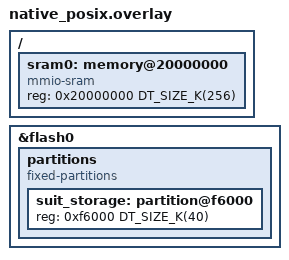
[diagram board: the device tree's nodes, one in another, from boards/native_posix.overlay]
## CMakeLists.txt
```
#
# Copyright (c) 2023 Nordic Semiconductor ASA
#
# SPDX-License-Identifier: LicenseRef-Nordic-5-Clause
#

cmake_minimum_required(VERSION 3.20.0)

find_package(Zephyr REQUIRED HINTS $ENV{ZEPHYR_BASE})

project(integration_test_suit_orchestrator)
include(../../cmake/test_template.cmake)

FILE(GLOB manifest_sources ../manifest/src/*.c)
target_sources(app PRIVATE
  ${manifest_sources}
  )

# Link with the CMake target, that includes SUIT platform internal APIs header
zephyr_library_link_libraries(suit)
zephyr_library_link_libraries(suit_orchestrator_interface)
zephyr_library_link_libraries(suit_utils)
zephyr_library_link_libraries(suit_storage_interface)
zephyr_library_link_libraries(suit_update_magic_values)
zephyr_library_link_libraries(suit_cache_interface)
zephyr_library_link_libraries(suit_execution_mode)
```

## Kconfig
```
#
# Copyright (c) 2025 Nordic Semiconductor ASA
#
# SPDX-License-Identifier: LicenseRef-Nordic-5-Clause
#

rsource "../../tests/Kconfig"

source "Kconfig.zephyr"
```

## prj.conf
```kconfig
#
# Copyright (c) 2023 Nordic Semiconductor ASA
#
# SPDX-License-Identifier: LicenseRef-Nordic-5-Clause
#

CONFIG_ZTEST=y
CONFIG_ZTEST_STACK_SIZE=4096

CONFIG_SUIT=y
CONFIG_SUIT_CRYPTO=y
CONFIG_SUIT_MCI=y
CONFIG_SUIT_MCI_IMPL_CUSTOM=y
CONFIG_PSA_WANT_ALG_ECDSA=y
CONFIG_SUIT_VALIDATOR=y
CONFIG_SUIT_VALIDATOR_IMPL_CUSTOM=y
CONFIG_SUIT_METADATA=y
CONFIG_SUIT_ORCHESTRATOR=y
CONFIG_SUIT_PROCESSOR=y
CONFIG_SUIT_PLATFORM=y
CONFIG_SUIT_LOG_LEVEL_DBG=y

CONFIG_SUIT_UTILS=y
CONFIG_SUIT_CACHE=y
# Use lower value to verify overflows
CONFIG_SUIT_CACHE_MAX_CACHES=5
CONFIG_SUIT_STORAGE=y
CONFIG_SUIT_MEMPTR_STORAGE=y
CONFIG_SUIT_EXECUTION_MODE=y

CONFIG_ZCBOR=y
CONFIG_ZCBOR_CANONICAL=y

CONFIG_FLASH=y

CONFIG_SUIT_DEVCONFIG=y
CONFIG_SUIT_PLAT_CHECK_COMPONENT_COMPATIBILITY=y
CONFIG_SUIT_PLAT_CHECK_CLASSES=y
CONFIG_SUIT_AUTHENTICATE=y

CONFIG_SUIT_DIGEST=y
CONFIG_SUIT_DIGEST_CACHE=y
CONFIG_SUIT_SINK_SELECTOR=y

CONFIG_SUIT_STREAM=y
CONFIG_SUIT_STREAM_SINK_DIGEST=y
CONFIG_SUIT_CHECK_IMAGE_MATCH=y

CONFIG_SUIT_STREAM_SINK_MEMPTR=y
CONFIG_SUIT_STREAM_SINK_FLASH=y
CONFIG_FLASH_MAP=y
CONFIG_SUIT_STREAM_SOURCE_MEMPTR=y
CONFIG_SUIT_STREAM_SOURCE_CACHE=y
```

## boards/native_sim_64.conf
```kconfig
#
# Copyright (c) 2023 Nordic Semiconductor ASA
#
# SPDX-License-Identifier: LicenseRef-Nordic-5-Clause
#

CONFIG_FLASH_SIMULATOR=y
CONFIG_FLASH_SIMULATOR_DOUBLE_WRITES=y
```

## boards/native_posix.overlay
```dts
/*
 * Copyright (c) 2023 Nordic Semiconductor ASA
 *
 * SPDX-License-Identifier: LicenseRef-Nordic-5-Clause
 */

&flash0 {
	partitions {
		compatible = "fixed-partitions";
		#address-cells = <1>;
		#size-cells = <1>;

		/* Use the last 40KB of NVM as suit storage. */
		suit_storage: partition@f6000 {
			reg = <0xf6000 DT_SIZE_K(40)>;
		};
	};
};

/ {
	sram0: memory@20000000 {
		compatible = "mmio-sram";
		reg = <0x20000000 DT_SIZE_K(256)>;
	};
};
```

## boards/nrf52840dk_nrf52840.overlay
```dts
/*
 * Copyright (c) 2023 Nordic Semiconductor ASA
 *
 * SPDX-License-Identifier: LicenseRef-Nordic-5-Clause
 */

&flash0 {
	partitions {
		compatible = "fixed-partitions";
		#address-cells = <1>;
		#size-cells = <1>;

		/* Use the last 44KB of NVM as suit storage. */
		suit_storage: partition@f5000 {
			reg = <0xf5000 DT_SIZE_K(44)>;
		};
	};
};
```

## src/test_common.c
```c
/*
 * Copyright (c) 2024 Nordic Semiconductor ASA
 *
 * SPDX-License-Identifier: LicenseRef-Nordic-5-Clause
 */

#include <zephyr/ztest.h>

#include <suit_execution_mode.h>

void check_startup_failure(void)
{
	suit_execution_mode_t mode_before = suit_execution_mode_get();
	bool has_failed = suit_execution_mode_failed();

	if (suit_execution_mode_booting()) {
		/* Update execution mode to leave transient states. */
		suit_execution_mode_startup_failed();

		/* If the device was booting - it should enter EXECUTION_MODE_FAIL_STARTUP state. */
		zassert_equal(false, suit_execution_mode_booting(),
			      "The device did not left boot mode");
		zassert_equal(false, suit_execution_mode_updating(),
			      "The device entered update mode");
		zassert_equal(true, suit_execution_mode_failed(),
			      "The device did not enter failed mode");
		zassert_equal(EXECUTION_MODE_FAIL_STARTUP, suit_execution_mode_get(),
			      "FAILED state not set after boot startup failed");
	} else if (suit_execution_mode_updating()) {
		/* Update execution mode to leave transient states. */
		suit_execution_mode_startup_failed();

		/* If the device was updating - it should enter EXECUTION_MODE_FAIL_STARTUP state.
		 */
		zassert_equal(false, suit_execution_mode_booting(), "The device entered boot mode");
		zassert_equal(false, suit_execution_mode_updating(),
			      "The device did not left update mode");
		zassert_equal(true, suit_execution_mode_failed(),
			      "The device did not enter failed mode");
		zassert_equal(EXECUTION_MODE_FAIL_STARTUP, suit_execution_mode_get(),
			      "FAILED state not set after update startup failed");
	} else {
		/* Update execution mode to leave transient states. */
		suit_execution_mode_startup_failed();

		/* If the device was in final state - it should stay in the same state state. */
		zassert_equal(false, suit_execution_mode_booting(), "The device entered boot mode");
		zassert_equal(false, suit_execution_mode_updating(),
			      "The device entered update mode");
		zassert_equal(has_failed, suit_execution_mode_failed(),
			      "The device changed failed mode");
		zassert_equal(mode_before, suit_execution_mode_get(),
			      "Unexpected execution mode change");
	}
}
```

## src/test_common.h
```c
/*
 * Copyright (c) 2024 Nordic Semiconductor ASA
 *
 * SPDX-License-Identifier: LicenseRef-Nordic-5-Clause
 */

#ifndef TEST_STARTUP_FAILURE_COMMON_H__
#define TEST_STARTUP_FAILURE_COMMON_H__

/**
 * @brief Assert that calling @ref suit_execution_mode_startup_failed in the current state
 *        is correctly handled.
 */
void check_startup_failure(void);

#endif /* TEST_STARTUP_FAILURE_COMMON_H__ */
```

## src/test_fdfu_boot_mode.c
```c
/*
 * Copyright (c) 2024 Nordic Semiconductor ASA
 *
 * SPDX-License-Identifier: LicenseRef-Nordic-5-Clause
 */

#include <zephyr/ztest.h>

#include <suit_orchestrator.h>
#include <suit_storage.h>
#include <suit_execution_mode.h>

#include <zephyr/drivers/flash.h>
#include <zephyr/storage/flash_map.h>
#include <suit_plat_mem_util.h>

#if DT_NODE_EXISTS(DT_NODELABEL(cpuapp_suit_storage))
#define SUIT_STORAGE_OFFSET FIXED_PARTITION_OFFSET(cpuapp_suit_storage)
#define SUIT_STORAGE_SIZE   FIXED_PARTITION_SIZE(cpuapp_suit_storage)
#else
#define SUIT_STORAGE_OFFSET FIXED_PARTITION_OFFSET(suit_storage)
#define SUIT_STORAGE_SIZE   FIXED_PARTITION_SIZE(suit_storage)
#endif
#define SUIT_STORAGE_ADDRESS suit_plat_mem_nvm_ptr_get(SUIT_STORAGE_OFFSET)
#define ZEPHYR_FLASH_EB_SIZE DT_PROP(DT_CHOSEN(zephyr_flash), erase_block_size)

/* RFC4122 uuid5(nordic_vid, 'test_sample_recovery')
 */
static const suit_manifest_class_id_t recovery_class_id = {{0x74, 0xa0, 0xc6, 0xe7, 0xa9, 0x2a,
							    0x56, 0x00, 0x9c, 0x5d, 0x30, 0xee,
							    0x87, 0x8b, 0x06, 0xba}};

/* Empty recovery envelope with invoke sequence */
extern const uint8_t manifest_recovery_no_validate_buf[];
extern const size_t manifest_recovery_no_validate_len;

/* Empty recovery envelope with invoke and failig validate sequences */
extern const uint8_t manifest_recovery_validate_fail_buf[];
extern const size_t manifest_recovery_validate_fail_len;

/* Empty recovery envelope with validate, invoke and failing load sequences */
extern const uint8_t manifest_recovery_validate_load_fail_buf[];
extern const size_t manifest_recovery_validate_load_fail_len;

/* Empty recovery envelope with validate and load sequences */
extern const uint8_t manifest_recovery_validate_load_no_invoke_buf[];
extern const size_t manifest_recovery_validate_load_no_invoke_len;

/* Empty recovery envelope with validate, load and failing invoke sequences */
extern const uint8_t manifest_recovery_validate_load_invoke_fail_buf[];
extern const size_t manifest_recovery_validate_load_invoke_fail_len;

/* Empty recovery envelope with validate, load and invoke sequences */
extern const uint8_t manifest_recovery_validate_load_invoke_buf[];
extern const size_t manifest_recovery_validate_load_invoke_len;

/* Valid recovery envelope */
extern uint8_t manifest_valid_recovery_buf[];
extern size_t manifest_valid_recovery_len;

/* Originally valid recovery envelope with manipulated single byte */
extern const uint8_t manifest_manipulated_recovery_buf[];
extern const size_t manifest_manipulated_recovery_len;

/* Random bytes, attached to the envelopes as FW. */
extern const uint8_t sample_fw_buf[];
extern const size_t sample_fw_len;
extern const uintptr_t sample_recovery_fw_address;

static void *setup_install_recovery_fw(void)
{
	int err = 0;
	uint8_t *sample_recovery_fw_ptr = suit_plat_mem_ptr_get(sample_recovery_fw_address);
	uintptr_t sample_recovery_fw_offset = suit_plat_mem_nvm_offset_get(sample_recovery_fw_ptr);

	/* Clear the whole application area */
	const struct device *fdev = SUIT_PLAT_INTERNAL_NVM_DEV;

	zassert_not_null(fdev, "Unable to find a driver to erase storage area");

	if (sample_fw_len > ZEPHYR_FLASH_EB_SIZE) {
		err = flash_erase(fdev, sample_recovery_fw_offset, sample_fw_len);
	} else {
		err = flash_erase(fdev, sample_recovery_fw_offset, ZEPHYR_FLASH_EB_SIZE);
	}
	zassert_equal(0, err, "Unable to erase test FW area before test execution");

	err = flash_write(fdev, sample_recovery_fw_offset, sample_fw_buf, sample_fw_len);
	zassert_equal(0, err, "Unable to write test FW area before test execution");

	return NULL;
}

static void setup_erased_flash(void)
{
	/* Execute SUIT storage init, so the MPI area is copied into a backup region. */
	int err = suit_storage_init();

	zassert_equal(SUIT_PLAT_SUCCESS, err, "Failed to init and backup suit storage (%d)", err);

	/* Clear the whole application area */
	const struct device *fdev = SUIT_PLAT_INTERNAL_NVM_DEV;

	zassert_not_null(fdev, "Unable to find a driver to erase storage area");

	err = flash_erase(fdev, SUIT_STORAGE_OFFSET, SUIT_STORAGE_SIZE);
	zassert_equal(0, err, "Unable to erase storage before test execution");

	suit_plat_err_t ret = suit_storage_flags_clear(SUIT_FLAG_RECOVERY);

	zassert_equal(SUIT_PLAT_SUCCESS, ret,
		      "Unable to clear recovery flag before test execution");

	ret = suit_storage_flags_clear(SUIT_FLAG_FOREGROUND_DFU);
	zassert_equal(SUIT_PLAT_SUCCESS, ret,
		      "Unable to clear foreground DFU flag before test execution");

	/* Recover MPI area from the backup region. */
	err = suit_storage_init();
	zassert_equal(SUIT_PLAT_SUCCESS, err, "Failed to recover MPI area from backup (%d)", err);
}

static void setup_install_envelope(const suit_manifest_class_id_t *class_id, const uint8_t *buf,
				   size_t len)
{
	suit_plat_err_t err = suit_storage_install_envelope(class_id, (uint8_t *)buf, len);

	zassert_equal(SUIT_PLAT_SUCCESS, err,
		      "Unable to install envelope before test execution (0x%x, %d)", buf, len);
}

static void setup_fdfu_flag(void)
{
	zassert_equal(SUIT_PLAT_SUCCESS, suit_storage_flags_set(SUIT_FLAG_FOREGROUND_DFU),
		      "Unable to set foreground DFU flag before test execution");
}

ZTEST_SUITE(orchestrator_fdfu_boot_tests, NULL, setup_install_recovery_fw, NULL, NULL, NULL);

ZTEST(orchestrator_fdfu_boot_tests, test_fdfu_no_recovery_envelope)
{
	/* GIVEN empty flash (suit storage is erased)... */
	setup_erased_flash();
	/* ... and update candidate flag is not set... */
	/* ... and foreground DFU flag is set */
	setup_fdfu_flag();
	/* ... and orchestrator is initialized... */
	zassert_equal(0, suit_orchestrator_init(),
		      "Orchestrator not initialized before test execution");
	/* ... and the execution mode is set to foreground DFU boot */
	zassert_equal(EXECUTION_MODE_INVOKE_FOREGROUND_DFU, suit_execution_mode_get(),
		      "Unexpected execution mode before test execution");

	/* WHEN orchestrator is executed */
	int err = suit_orchestrator_entry();

	/* THEN orchestrator fails (hard)... */
	zassert_equal(-ENOENT, err, "Orchestrator did not fail");
	/* ... and the foreground DFU flag is set... */
	zassert_equal(SUIT_PLAT_ERR_NOT_FOUND, suit_storage_flags_check(SUIT_FLAG_RECOVERY),
		      "Recovery flag set");
	zassert_equal(SUIT_PLAT_SUCCESS, suit_storage_flags_check(SUIT_FLAG_FOREGROUND_DFU),
		      "Foreground DFU flag not set");
	/* ... and the execution mode is set to the FAIL INVOKE FDFU */
	zassert_equal(EXECUTION_MODE_FAIL_INVOKE_FOREGROUND_DFU, suit_execution_mode_get(),
		      "Execution mode not changed to the FAIL INVOKE FDFU");
	/* ... and execution mode indicates a failed state */
	zassert_equal(true, suit_execution_mode_failed(), "The device does not enter failed mode");
	/* ... and execution mode does not indicate boot mode */
	zassert_equal(false, suit_execution_mode_booting(), "The device did not left boot mode");
	/* ... and execution mode does not indicate update mode */
	zassert_equal(false, suit_execution_mode_updating(), "The device entered update mode");
}

ZTEST(orchestrator_fdfu_boot_tests, test_fdfu_invalid_recovery_envelope)
{
	/* GIVEN empty flash (suit storage is erased)... */
	setup_erased_flash();
	/* ... and recovery envelope is installed... */
	setup_install_envelope(&recovery_class_id, manifest_manipulated_recovery_buf,
			       manifest_manipulated_recovery_len);
	/* ... and update candidate flag is not set... */
	/* ... and foreground DFU flag is set */
	setup_fdfu_flag();
	/* ... and orchestrator is initialized... */
	zassert_equal(0, suit_orchestrator_init(),
		      "Orchestrator not initialized before test execution");
	/* ... and the execution mode is set to foreground DFU boot */
	zassert_equal(EXECUTION_MODE_INVOKE_FOREGROUND_DFU, suit_execution_mode_get(),
		      "Unexpected execution mode before test execution");

	/* WHEN orchestrator is executed */
	int err = suit_orchestrator_entry();

	/* THEN orchestrator fails (hard)... */
	zassert_equal(-ENOEXEC, err, "Orchestrator did not fail");
	/* ... and the foreground DFU flag is set... */
	zassert_equal(SUIT_PLAT_ERR_NOT_FOUND, suit_storage_flags_check(SUIT_FLAG_RECOVERY),
		      "Recovery flag set");
	zassert_equal(SUIT_PLAT_SUCCESS, suit_storage_flags_check(SUIT_FLAG_FOREGROUND_DFU),
		      "Foreground DFU flag not set");
	/* ... and the execution mode is set to the FAIL INVOKE FDFU */
	zassert_equal(EXECUTION_MODE_FAIL_INVOKE_FOREGROUND_DFU, suit_execution_mode_get(),
		      "Execution mode not changed to the FAIL INVOKE FDFU");
}

ZTEST(orchestrator_fdfu_boot_tests, test_fdfu_valid_recovery_envelope)
{
	/* GIVEN empty flash (suit storage is erased)... */
	setup_erased_flash();
	/* ... and recovery envelope is installed... */
	setup_install_envelope(&recovery_class_id, manifest_valid_recovery_buf,
			       manifest_valid_recovery_len);
	/* ... and update candidate flag is not set... */
	/* ... and foreground DFU flag is set */
	setup_fdfu_flag();
	/* ... and orchestrator is initialized... */
	zassert_equal(0, suit_orchestrator_init(),
		      "Orchestrator not initialized before test execution");
	/* ... and the execution mode is set to foreground DFU boot */
	zassert_equal(EXECUTION_MODE_INVOKE_FOREGROUND_DFU, suit_execution_mode_get(),
		      "Unexpected execution mode before test execution");

	/* WHEN orchestrator is executed */
	int err = suit_orchestrator_entry();

	/* THEN orchestrator succeeds... */
	zassert_equal(0, err, "Orchestrator not initialized");
	/* ... and the foreground DFU flag is set... */
	zassert_equal(SUIT_PLAT_ERR_NOT_FOUND, suit_storage_flags_check(SUIT_FLAG_RECOVERY),
		      "Recovery flag set");
	zassert_equal(SUIT_PLAT_SUCCESS, suit_storage_flags_check(SUIT_FLAG_FOREGROUND_DFU),
		      "Foreground DFU flag not set");
	/* ... and the execution mode is set to the POST INVOKE FDFU */
	zassert_equal(EXECUTION_MODE_POST_INVOKE_FOREGROUND_DFU, suit_execution_mode_get(),
		      "Execution mode not changed to the POST INVOKE FDFU");
	/* ... and execution mode does not indicate a failed state */
	zassert_equal(false, suit_execution_mode_failed(), "The device entered failed mode");
	/* ... and execution mode does not indicate boot mode */
	zassert_equal(false, suit_execution_mode_booting(), "The device did not left boot mode");
	/* ... and execution mode does not indicate update mode */
	zassert_equal(false, suit_execution_mode_updating(), "The device entered update mode");
}

ZTEST(orchestrator_fdfu_boot_tests, test_fdfu_seq_no_validate)
{
	/* GIVEN empty flash (suit storage is erased)... */
	setup_erased_flash();
	/* ... and recovery envelope is installed... */
	setup_install_envelope(&recovery_class_id, manifest_recovery_no_validate_buf,
			       manifest_recovery_no_validate_len);
	/* ... and update candidate flag is not set... */
	/* ... and foreground DFU flag is set */
	setup_fdfu_flag();
	/* ... and orchestrator is initialized... */
	zassert_equal(0, suit_orchestrator_init(),
		      "Orchestrator not initialized before test execution");
	/* ... and the execution mode is set to foreground DFU boot */
	zassert_equal(EXECUTION_MODE_INVOKE_FOREGROUND_DFU, suit_execution_mode_get(),
		      "Unexpected execution mode before test execution");

	/* WHEN orchestrator is executed */
	int err = suit_orchestrator_entry();

	/* THEN orchestrator succeeds... */
	zassert_equal(0, err, "Envelope without validate sequence not accepted (err: %d)", err);
	/* ... and the foreground DFU flag is set... */
	zassert_equal(SUIT_PLAT_ERR_NOT_FOUND, suit_storage_flags_check(SUIT_FLAG_RECOVERY),
		      "Recovery flag set");
	zassert_equal(SUIT_PLAT_SUCCESS, suit_storage_flags_check(SUIT_FLAG_FOREGROUND_DFU),
		      "Foreground DFU flag not set");
	/* ... and the execution mode is set to the POST INVOKE RECOVERY */
	zassert_equal(EXECUTION_MODE_POST_INVOKE_FOREGROUND_DFU, suit_execution_mode_get(),
		      "Execution mode not changed to the POST INVOKE FDFU");
}

ZTEST(orchestrator_fdfu_boot_tests, test_fdfu_seq_validate_fail)
{
	/* GIVEN empty flash (suit storage is erased)... */
	setup_erased_flash();
	/* ... and recovery envelope with failing suit-validate sequence is installed... */
	setup_install_envelope(&recovery_class_id, manifest_recovery_validate_fail_buf,
			       manifest_recovery_validate_fail_len);
	/* ... and update candidate flag is not set... */
	/* ... and foreground DFU flag is set */
	setup_fdfu_flag();
	/* ... and orchestrator is initialized... */
	zassert_equal(0, suit_orchestrator_init(),
		      "Orchestrator not initialized before test execution");
	/* ... and the execution mode is set to foreground DFU boot */
	zassert_equal(EXECUTION_MODE_INVOKE_FOREGROUND_DFU, suit_execution_mode_get(),
		      "Unexpected execution mode before test execution");

	/* WHEN orchestrator is executed */
	int err = suit_orchestrator_entry();

	/* THEN orchestrator fails (hard)... */
	zassert_equal(-EILSEQ, err, "Orchestrator did not fail");
	/* ... and the foreground DFU flag is set... */
	zassert_equal(SUIT_PLAT_ERR_NOT_FOUND, suit_storage_flags_check(SUIT_FLAG_RECOVERY),
		      "Recovery flag set");
	zassert_equal(SUIT_PLAT_SUCCESS, suit_storage_flags_check(SUIT_FLAG_FOREGROUND_DFU),
		      "Foreground DFU flag not set");
	/* ... and the execution mode is set to the FAIL INVOKE FDFU */
	zassert_equal(EXECUTION_MODE_FAIL_INVOKE_FOREGROUND_DFU, suit_execution_mode_get(),
		      "Execution mode not changed to the FAIL INVOKE FDFU");
}

ZTEST(orchestrator_fdfu_boot_tests, test_fdfu_seq_validate_load_fail)
{
	/* GIVEN empty flash (suit storage is erased)... */
	setup_erased_flash();
	/* ... and recovery envelope with failing suit-load sequence is installed... */
	setup_install_envelope(&recovery_class_id, manifest_recovery_validate_load_fail_buf,
			       manifest_recovery_validate_load_fail_len);
	/* ... and update candidate flag is not set... */
	/* ... and foreground DFU flag is set */
	setup_fdfu_flag();
	/* ... and orchestrator is initialized... */
	zassert_equal(0, suit_orchestrator_init(),
		      "Orchestrator not initialized before test execution");
	/* ... and the execution mode is set to foreground DFU boot */
	zassert_equal(EXECUTION_MODE_INVOKE_FOREGROUND_DFU, suit_execution_mode_get(),
		      "Unexpected execution mode before test execution");

	/* WHEN orchestrator is executed */
	int err = suit_orchestrator_entry();

	/* THEN orchestrator fails (hard)... */
	zassert_equal(-EILSEQ, err, "Orchestrator did not fail");
	/* ... and the foreground DFU flag is set... */
	zassert_equal(SUIT_PLAT_ERR_NOT_FOUND, suit_storage_flags_check(SUIT_FLAG_RECOVERY),
		      "Recovery flag set");
	zassert_equal(SUIT_PLAT_SUCCESS, suit_storage_flags_check(SUIT_FLAG_FOREGROUND_DFU),
		      "Foreground DFU flag not set");
	/* ... and the execution mode is set to the FAIL INVOKE FDFU */
	zassert_equal(EXECUTION_MODE_FAIL_INVOKE_FOREGROUND_DFU, suit_execution_mode_get(),
		      "Execution mode not changed to the FAIL INVOKE FDFU");
}

ZTEST(orchestrator_fdfu_boot_tests, test_fdfu_seq_validate_load_no_invoke)
{
	/* GIVEN empty flash (suit storage is erased)... */
	setup_erased_flash();
	/* ... and recovery envelope without suit-invoke sequence is installed... */
	setup_install_envelope(&recovery_class_id, manifest_recovery_validate_load_no_invoke_buf,
			       manifest_recovery_validate_load_no_invoke_len);
	/* ... and update candidate flag is not set... */
	/* ... and foreground DFU flag is set */
	setup_fdfu_flag();
	/* ... and orchestrator is initialized... */
	zassert_equal(0, suit_orchestrator_init(),
		      "Orchestrator not initialized before test execution");
	/* ... and the execution mode is set to foreground DFU boot */
	zassert_equal(EXECUTION_MODE_INVOKE_FOREGROUND_DFU, suit_execution_mode_get(),
		      "Unexpected execution mode before test execution");

	/* WHEN orchestrator is executed */
	int err = suit_orchestrator_entry();

	/* THEN orchestrator fails (hard)... */
	zassert_equal(-EILSEQ, err, "Orchestrator did not fail");
	/* ... and the foreground DFU flag is set... */
	zassert_equal(SUIT_PLAT_ERR_NOT_FOUND, suit_storage_flags_check(SUIT_FLAG_RECOVERY),
		      "Recovery flag set");
	zassert_equal(SUIT_PLAT_SUCCESS, suit_storage_flags_check(SUIT_FLAG_FOREGROUND_DFU),
		      "Foreground DFU flag not set");
	/* ... and the execution mode is set to the FAIL INVOKE FDFU */
	zassert_equal(EXECUTION_MODE_FAIL_INVOKE_FOREGROUND_DFU, suit_execution_mode_get(),
		      "Execution mode not changed to the FAIL INVOKE FDFU");
}

ZTEST(orchestrator_fdfu_boot_tests, test_fdfu_seq_validate_load_invoke_fail)
{
	/* GIVEN empty flash (suit storage is erased)... */
	setup_erased_flash();
	/* ... and recovery envelope with failing suit-invoke sequence is installed... */
	setup_install_envelope(&recovery_class_id, manifest_recovery_validate_load_invoke_fail_buf,
			       manifest_recovery_validate_load_invoke_fail_len);
	/* ... and update candidate flag is not set... */
	/* ... and foreground DFU flag is set */
	setup_fdfu_flag();
	/* ... and orchestrator is initialized... */
	zassert_equal(0, suit_orchestrator_init(),
		      "Orchestrator not initialized before test execution");
	/* ... and the execution mode is set to foreground DFU boot */
	zassert_equal(EXECUTION_MODE_INVOKE_FOREGROUND_DFU, suit_execution_mode_get(),
		      "Unexpected execution mode before test execution");

	/* WHEN orchestrator is executed */
	int err = suit_orchestrator_entry();

	/* THEN orchestrator fails (hard)... */
	zassert_equal(-EILSEQ, err, "Orchestrator did not fail");
	/* ... and the foreground DFU flag is set... */
	zassert_equal(SUIT_PLAT_ERR_NOT_FOUND, suit_storage_flags_check(SUIT_FLAG_RECOVERY),
		      "Recovery flag set");
	zassert_equal(SUIT_PLAT_SUCCESS, suit_storage_flags_check(SUIT_FLAG_FOREGROUND_DFU),
		      "Foreground DFU flag not set");
	/* ... and the execution mode is set to the FAIL INVOKE FDFU */
	zassert_equal(EXECUTION_MODE_FAIL_INVOKE_FOREGROUND_DFU, suit_execution_mode_get(),
		      "Execution mode not changed to the FAIL INVOKE FDFU");
}

ZTEST(orchestrator_fdfu_boot_tests, test_fdfu_seq_validate_load_invoke)
{
	/* GIVEN empty flash (suit storage is erased)... */
	setup_erased_flash();
	/* ... and recovery envelope without dependencies is installed... */
	setup_install_envelope(&recovery_class_id, manifest_recovery_validate_load_invoke_buf,
			       manifest_recovery_validate_load_invoke_len);
	/* ... and update candidate flag is not set... */
	/* ... and foreground DFU flag is set */
	setup_fdfu_flag();
	/* ... and orchestrator is initialized... */
	zassert_equal(0, suit_orchestrator_init(),
		      "Orchestrator not initialized before test execution");
	/* ... and the execution mode is set to foreground DFU boot */
	zassert_equal(EXECUTION_MODE_INVOKE_FOREGROUND_DFU, suit_execution_mode_get(),
		      "Unexpected execution mode before test execution");

	/* WHEN orchestrator is executed */
	int err = suit_orchestrator_entry();

	/* THEN orchestrator fails succeeds... */
	zassert_equal(0, err, "Orchestrator not initialized");
	/* ... and the foreground DFU flag is set... */
	zassert_equal(SUIT_PLAT_ERR_NOT_FOUND, suit_storage_flags_check(SUIT_FLAG_RECOVERY),
		      "Recovery flag set");
	zassert_equal(SUIT_PLAT_SUCCESS, suit_storage_flags_check(SUIT_FLAG_FOREGROUND_DFU),
		      "Foreground DFU flag not set");
	/* ... and the execution mode is set to the POST INVOKE FDFU */
	zassert_equal(EXECUTION_MODE_POST_INVOKE_FOREGROUND_DFU, suit_execution_mode_get(),
		      "Execution mode not changed to the POST INVOKE FDFU");
}
```

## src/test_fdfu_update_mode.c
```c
/*
 * Copyright (c) 2024 Nordic Semiconductor ASA
 *
 * SPDX-License-Identifier: LicenseRef-Nordic-5-Clause
 */

#include <zephyr/ztest.h>

#include <suit_orchestrator.h>
#include <suit_storage.h>
#include <suit_execution_mode.h>
#include <suit_dfu_cache.h>

#include <zephyr/drivers/flash.h>
#include <zephyr/storage/flash_map.h>
#include <suit_plat_mem_util.h>

#if DT_NODE_EXISTS(DT_NODELABEL(cpuapp_suit_storage))
#define SUIT_STORAGE_OFFSET FIXED_PARTITION_OFFSET(cpuapp_suit_storage)
#define SUIT_STORAGE_SIZE   FIXED_PARTITION_SIZE(cpuapp_suit_storage)
#else
#define SUIT_STORAGE_OFFSET FIXED_PARTITION_OFFSET(suit_storage)
#define SUIT_STORAGE_SIZE   FIXED_PARTITION_SIZE(suit_storage)
#endif

/* RFC4122 uuid5(nordic_vid, 'test_sample_app') */
static const suit_manifest_class_id_t supported_class_id = {{0x5b, 0x46, 0x9f, 0xd1, 0x90, 0xee,
							     0x53, 0x9c, 0xa3, 0x18, 0x68, 0x1b,
							     0x03, 0x69, 0x5e, 0x36}};

/* RFC4122 uuid5(nordic_vid, 'test_sample_root') */
static const suit_manifest_class_id_t root_class_id = {{0x97, 0x05, 0x48, 0x23, 0x4c, 0x3d, 0x59,
							0xa1, 0x89, 0x86, 0xa5, 0x46, 0x60, 0xa1,
							0x4b, 0x0a}};

/* Valid root envelope */
extern uint8_t manifest_valid_buf[];
extern size_t manifest_valid_len;

/* Valid recovery envelope */
extern uint8_t manifest_valid_recovery_buf[];
extern size_t manifest_valid_recovery_len;

static void setup_erased_flash(void)
{
	/* Clear the whole application area */
	const struct device *fdev = SUIT_PLAT_INTERNAL_NVM_DEV;

	zassert_not_null(fdev, "Unable to find a driver to erase storage area");

	int err = flash_erase(fdev, SUIT_STORAGE_OFFSET, SUIT_STORAGE_SIZE);

	zassert_equal(0, err, "Unable to erase storage before test execution");

	suit_plat_err_t ret = suit_storage_flags_clear(SUIT_FLAG_RECOVERY);

	zassert_equal(SUIT_PLAT_SUCCESS, ret,
		      "Unable to clear recovery flag before test execution");

	ret = suit_storage_flags_clear(SUIT_FLAG_FOREGROUND_DFU);
	zassert_equal(SUIT_PLAT_SUCCESS, ret,
		      "Unable to clear foreground DFU flag before test execution");

	/* Recover MPI area from the backup region. */
	err = suit_storage_init();
	zassert_equal(SUIT_PLAT_SUCCESS, err, "Failed to recover MPI area from backup (%d)", err);
}

static void setup_update_candidate(const uint8_t *buf, size_t len)
{
	zassert_not_null(buf, "NULL buf");

	suit_plat_mreg_t update_candidate[1] = {{
		.mem = buf,
		.size = len,
	}};

	int err = suit_storage_update_cand_set(update_candidate, ARRAY_SIZE(update_candidate));

	zassert_equal(SUIT_PLAT_SUCCESS, err,
		      "Unable to set update candidate before test execution (0x%x, %d)", buf, len);
}

static void assert_post_fdfu_install_state(void)
{
	const suit_plat_mreg_t *regions = NULL;
	size_t len = 0;

	/* Each install attempt must at the end: */
	/* - clear the candidate availability flag */
	suit_plat_err_t ret = suit_storage_update_cand_get(&regions, &len);

	zassert_equal(SUIT_PLAT_ERR_NOT_FOUND, ret, "Update candidate presence not cleared");
	/* - clear the foreground DFU flag */
	zassert_equal(SUIT_PLAT_ERR_NOT_FOUND, suit_storage_flags_check(SUIT_FLAG_FOREGROUND_DFU),
		      "Foreground DFU flag not cleared");
	/* - do not modify the execution mode */
	zassert_equal(EXECUTION_MODE_INSTALL_FOREGROUND_DFU, suit_execution_mode_get(),
		      "Execution mode modified");
}

static void assert_post_fdfu_install_failed_state(void)
{
	const suit_plat_mreg_t *regions = NULL;
	size_t len = 0;

	/* Each install attempt must at the end: */
	/* - clear the candidate availability flag */
	suit_plat_err_t ret = suit_storage_update_cand_get(&regions, &len);

	zassert_equal(SUIT_PLAT_ERR_NOT_FOUND, ret, "Update candidate presence not cleared");
	/* - do not modify the foreground DFU flag */
	zassert_equal(SUIT_PLAT_ERR_NOT_FOUND, suit_storage_flags_check(SUIT_FLAG_RECOVERY),
		      "Recovery flag changed");
	zassert_equal(SUIT_PLAT_SUCCESS, suit_storage_flags_check(SUIT_FLAG_FOREGROUND_DFU),
		      "Foreground DFU flag changed");
	/* - do not modify the execution mode */
	zassert_equal(EXECUTION_MODE_INSTALL_FOREGROUND_DFU, suit_execution_mode_get(),
		      "Execution mode modified");
}

static void orchestrator_tests_cleanup(void *fixture)
{
	(void)fixture;
	suit_dfu_cache_deinitialize();
}

static void enter_fdfu_mode(void *fixture)
{
	int err = suit_storage_init();

	zassert_equal(SUIT_PLAT_SUCCESS, err, "Failed to init and backup suit storage (%d)", err);

	setup_erased_flash();

	zassert_equal(SUIT_PLAT_SUCCESS, suit_storage_flags_set(SUIT_FLAG_FOREGROUND_DFU),
		      "Unable to set foreground DFU flag before test execution");
}

ZTEST_SUITE(orchestrator_fdfu_update_tests, NULL, NULL, enter_fdfu_mode,
	    orchestrator_tests_cleanup, NULL);

ZTEST(orchestrator_fdfu_update_tests, test_fdfu_successful_update)
{
	const uint8_t *addr;
	size_t size;

	/* GIVEN valid update candidate in suit storage... */
	setup_update_candidate(manifest_valid_buf, manifest_valid_len);
	/* ... and suit orchestrator is initialized... */
	zassert_equal(0, suit_orchestrator_init(), "Orchestrator not initialized");
	/* ... and the execution mode is set to install foreground DFU mode */
	zassert_equal(EXECUTION_MODE_INSTALL_FOREGROUND_DFU, suit_execution_mode_get(),
		      "Unexpected execution mode before test execution");

	/* WHEN orchestrator is launched */
	int err = suit_orchestrator_entry();

	/* THEN installation is performed successfully... */
	/* ... and orchestrator exits without an error... */
	zassert_equal(0, err, "Unexpected error code");
	/* ... and the application envelope get installed... */
	err = suit_storage_installed_envelope_get(&supported_class_id, &addr, &size);
	zassert_equal(SUIT_PLAT_SUCCESS, err,
		      "The application envelope was not installed after successful update");
	/* ... and the root envelope get installed... */
	err = suit_storage_installed_envelope_get(&root_class_id, &addr, &size);
	zassert_equal(SUIT_PLAT_SUCCESS, err,
		      "The root envelope was not installed after successful update");
	/* ... and the candidate availability flag is cleared */
	assert_post_fdfu_install_state();
}

ZTEST(orchestrator_fdfu_update_tests, test_fdfu_successful_update_and_boot)
{
	const uint8_t *addr_boot;
	size_t size_boot;
	const uint8_t *addr_update;
	size_t size_update;

	/* GIVEN valid update candidate in suit storage... */
	setup_update_candidate(manifest_valid_buf, manifest_valid_len);
	/* ... and suit orchestrator is initialized... */
	zassert_equal(0, suit_orchestrator_init(), "Orchestrator not initialized first time");
	/* ... and the execution mode is set to install foreground DFU mode */
	zassert_equal(EXECUTION_MODE_INSTALL_FOREGROUND_DFU, suit_execution_mode_get(),
		      "Unexpected execution mode before test execution");
	/* ... and orchestrator is launched first time to perform successful update... */
	zassert_equal(0, suit_orchestrator_entry(), "Unsuccessful first orchestrator launch");
	/* ... and the root envelope is installed... */
	int err = suit_storage_installed_envelope_get(&root_class_id, &addr_boot, &size_boot);

	zassert_equal(SUIT_PLAT_SUCCESS, err,
		      "The root envelope was not installed after successful update");
	/* ... and the application envelope is installed... */
	err = suit_storage_installed_envelope_get(&supported_class_id, &addr_boot, &size_boot);
	zassert_equal(SUIT_PLAT_SUCCESS, err,
		      "The application envelope was not installed after successful update");
	/* ... and the candidate availability flag is cleared */
	assert_post_fdfu_install_state();

	/* WHEN orchestrator is initialized again (reboot simulation)... */
	zassert_equal(0, suit_orchestrator_init(), "Orchestrator not initialized second time");
	/* ... and the execution mode is set to invoke mode */
	zassert_equal(EXECUTION_MODE_INVOKE, suit_execution_mode_get(),
		      "Unexpected execution mode before test execution");
	/* ... and orchestrator is launched again */
	err = suit_orchestrator_entry();

	/* THEN installed SW is invoked successfully (orchestrator returns no error)... */
	zassert_equal(0, err, "Unexpected error code");
	/* ... and the root envelope remains installed... */
	err = suit_storage_installed_envelope_get(&root_class_id, &addr_update, &size_update);
	zassert_equal(SUIT_PLAT_SUCCESS, err,
		      "The root envelope was not installed after successful update");
	/* ... and the envelope remains installed... */
	err = suit_storage_installed_envelope_get(&supported_class_id, &addr_update, &size_update);
	zassert_equal(SUIT_PLAT_SUCCESS, err,
		      "The application envelope was not installed after successful update");
	/* .. and the same index in SUIT storage is used... */
	zassert_equal(addr_boot, addr_update,
		      "The envelope was not installed in the same SUIT storage slot");
	/* ... and the execution mode is set to post invoke mode */
	zassert_equal(EXECUTION_MODE_POST_INVOKE, suit_execution_mode_get(),
		      "Unexpected execution mode after test execution");
}

ZTEST(orchestrator_fdfu_update_tests, test_fdfu_invalid_exec_mode)
{
	/* GIVEN suit storage does not indicate presence of update candidate... */
	setup_erased_flash();
	/* ... and orchestrator is initialized... */
	zassert_equal(0, suit_orchestrator_init(), "Orchestrator not initialized");
	/* ... and the execution mode is forced to foreground DFU install mode */
	zassert_equal(SUIT_PLAT_SUCCESS,
		      suit_execution_mode_set(EXECUTION_MODE_INSTALL_FOREGROUND_DFU),
		      "Unable to override execution mode before test execution");

	/* WHEN orchestrator is launched */
	int err = suit_orchestrator_entry();

	/* THEN orchestrator returns error code... */
	zassert_equal(-EMSGSIZE, err, "Unexpected error code");
	/* ... and the candidate availability flag remains cleared */
	assert_post_fdfu_install_state();
}

ZTEST(orchestrator_fdfu_update_tests, test_fdfu_independent_updates_denied)
{
	/* GIVEN suit storage contains recovery FW update... */
	setup_update_candidate(manifest_valid_recovery_buf, manifest_valid_recovery_len);

	/* ... and orchestrator is initialized... */
	zassert_equal(0, suit_orchestrator_init(), "Orchestrator not initialized");
	/* ... and the execution mode is set to install foreground DFU mode */
	zassert_equal(EXECUTION_MODE_INSTALL_FOREGROUND_DFU, suit_execution_mode_get(),
		      "Unexpected execution mode before test execution");

	/* WHEN orchestrator is launched */
	int err = suit_orchestrator_entry();

	/* THEN orchestrator returns error code... */
	zassert_equal(-EACCES, err, "Unexpected error code");
	/* ... and the candidate availability flag is cleared */
	assert_post_fdfu_install_failed_state();
}
```

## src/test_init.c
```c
/*
 * Copyright (c) 2024 Nordic Semiconductor ASA
 *
 * SPDX-License-Identifier: LicenseRef-Nordic-5-Clause
 */

#include <zephyr/ztest.h>

#include <suit_orchestrator.h>
#include <suit_storage.h>
#include <suit_execution_mode.h>

#include <zephyr/drivers/flash.h>
#include <zephyr/storage/flash_map.h>
#include <suit_plat_mem_util.h>
#include "test_common.h"

#if DT_NODE_EXISTS(DT_NODELABEL(cpuapp_suit_storage))
#define SUIT_STORAGE_OFFSET FIXED_PARTITION_OFFSET(cpuapp_suit_storage)
#define SUIT_STORAGE_SIZE   FIXED_PARTITION_SIZE(cpuapp_suit_storage)
#else
#define SUIT_STORAGE_OFFSET FIXED_PARTITION_OFFSET(suit_storage)
#define SUIT_STORAGE_SIZE   FIXED_PARTITION_SIZE(suit_storage)
#endif
#define SUIT_STORAGE_ADDRESS suit_plat_mem_nvm_ptr_get(SUIT_STORAGE_OFFSET)

/* Valid envelope */
extern uint8_t manifest_valid_buf[];
extern size_t manifest_valid_len;

static void setup_erased_flash(void)
{
	/* Execute SUIT storage init, so the MPI area is copied into a backup region. */
	int err = suit_storage_init();

	zassert_equal(SUIT_PLAT_SUCCESS, err, "Failed to init and backup suit storage (%d)", err);

	/* Clear the whole application area */
	const struct device *fdev = SUIT_PLAT_INTERNAL_NVM_DEV;

	zassert_not_null(fdev, "Unable to find a driver to erase storage area");

	err = flash_erase(fdev, SUIT_STORAGE_OFFSET, SUIT_STORAGE_SIZE);
	zassert_equal(0, err, "Unable to erase storage before test execution");

	suit_plat_err_t ret = suit_storage_flags_clear(SUIT_FLAG_RECOVERY);

	zassert_equal(SUIT_PLAT_SUCCESS, ret,
		      "Unable to clear recovery flag before test execution");

	ret = suit_storage_flags_clear(SUIT_FLAG_FOREGROUND_DFU);
	zassert_equal(SUIT_PLAT_SUCCESS, ret,
		      "Unable to clear foreground DFU flag before test execution");

	/* Recover MPI area from the backup region. */
	err = suit_storage_init();
	zassert_equal(SUIT_PLAT_SUCCESS, err, "Failed to recover MPI area from backup (%d)", err);
}

static void setup_update_candidate(const uint8_t *buf, size_t len)
{
	zassert_not_null(buf, "NULL buf");

	suit_plat_mreg_t update_candidate[1] = {{
		.mem = buf,
		.size = len,
	}};

	suit_plat_err_t err =
		suit_storage_update_cand_set(update_candidate, ARRAY_SIZE(update_candidate));

	zassert_equal(SUIT_PLAT_SUCCESS, err,
		      "Unable to set update candidate before test execution (0x%x, %d)", buf, len);
}

static void setup_recovery_flag(void)
{
	zassert_equal(SUIT_PLAT_SUCCESS, suit_storage_flags_set(SUIT_FLAG_RECOVERY),
		      "Unable to set recovery flag before test execution");
}

static void setup_fdfu_flag(void)
{
	zassert_equal(SUIT_PLAT_SUCCESS, suit_storage_flags_set(SUIT_FLAG_FOREGROUND_DFU),
		      "Unable to set foreground DFU flag before test execution");
}

ZTEST_SUITE(orchestrator_init_tests, NULL, NULL, NULL, NULL, NULL);

ZTEST(orchestrator_init_tests, test_orchestrator_sdfw_empty_storage)
{
	/* GIVEN empty flash (suit storage is erased)... */
	setup_erased_flash();
	/* ... and update candidate flag is not set... */
	/* ... and emergency flag is not set */

	/* WHEN orchestrator is initialized */
	int err = suit_orchestrator_init();

	/* THEN regular boot is triggered... */
	zassert_equal(EXECUTION_MODE_INVOKE, suit_execution_mode_get(),
		      "Regular boot not triggered");
	/* ... and orchestrator is initialized */
	zassert_equal(0, err, "Orchestrator not initialized");
	/* ... and execution mode does not indicate a failed state */
	zassert_equal(false, suit_execution_mode_failed(), "The device entered failed mode");
	/* ... and execution mode indicates boot mode */
	zassert_equal(true, suit_execution_mode_booting(), "The device did not enter boot mode");
	/* ... and execution mode does not indicate update mode */
	zassert_equal(false, suit_execution_mode_updating(), "The device entered update mode");
	/* ... and the startup failure is correctly handled */
	check_startup_failure();
}

ZTEST(orchestrator_init_tests, test_orchestrator_sdfw_empty_storage_with_update_flag)
{
	/* GIVEN empty flash (suit storage is erased)... */
	setup_erased_flash();
	/* ... and valid update candidate in suit storage... */
	setup_update_candidate(manifest_valid_buf, manifest_valid_len);
	/* ... and emergency flag is not set */

	/* WHEN orchestrator is initialized */
	int err = suit_orchestrator_init();

	/* THEN regular update is triggered... */
	zassert_equal(EXECUTION_MODE_INSTALL, suit_execution_mode_get(),
		      "Regular update not triggered");
	/* ... and orchestrator is initialized */
	zassert_equal(0, err, "Orchestrator not initialized");
	/* ... and execution mode does not indicate a failed state */
	zassert_equal(false, suit_execution_mode_failed(), "The device entered failed mode");
	/* ... and execution mode does not indicate boot mode */
	zassert_equal(false, suit_execution_mode_booting(), "The device entered boot mode");
	/* ... and execution mode indicates update mode */
	zassert_equal(true, suit_execution_mode_updating(), "The device did not enter update mode");
	/* ... and the startup failure is correctly handled */
	check_startup_failure();
}

ZTEST(orchestrator_init_tests, test_orchestrator_sdfw_empty_storage_with_recovery_flag)
{
	/* GIVEN empty flash (suit storage is erased)... */
	setup_erased_flash();
	/* ... and update candidate flag is not set... */
	/* ... and emergency flag is set */
	setup_recovery_flag();

	/* WHEN orchestrator is initialized */
	int err = suit_orchestrator_init();

	/* THEN emergency recovery is triggered... */
	zassert_equal(EXECUTION_MODE_INVOKE_RECOVERY, suit_execution_mode_get(),
		      "Recovery mode not triggered");
	/* ... and orchestrator is initialized */
	zassert_equal(0, err, "Orchestrator not initialized");
	/* ... and execution mode does not indicate a failed state */
	zassert_equal(false, suit_execution_mode_failed(), "The device entered failed mode");
	/* ... and execution mode indicates boot mode */
	zassert_equal(true, suit_execution_mode_booting(), "The device did not enter boot mode");
	/* ... and execution mode does not indicate update mode */
	zassert_equal(false, suit_execution_mode_updating(), "The device entered update mode");
	/* ... and the startup failure is correctly handled */
	check_startup_failure();
}

ZTEST(orchestrator_init_tests, test_orchestrator_sdfw_empty_storage_with_update_recovery_flag)
{
	/* GIVEN empty flash (suit storage is erased)... */
	setup_erased_flash();
	/* ... and valid update candidate in suit storage... */
	setup_update_candidate(manifest_valid_buf, manifest_valid_len);
	/* ... and emergency flag is set */
	setup_recovery_flag();

	/* WHEN orchestrator is initialized */
	int err = suit_orchestrator_init();

	/* THEN emergency recovery update is triggered... */
	zassert_equal(EXECUTION_MODE_INSTALL_RECOVERY, suit_execution_mode_get(),
		      "Emergency recovery update not triggered");
	/* ... and orchestrator is initialized */
	zassert_equal(0, err, "Orchestrator not initialized");
	/* ... and execution mode does not indicate a failed state */
	zassert_equal(false, suit_execution_mode_failed(), "The device entered failed mode");
	/* ... and execution mode does not indicate boot mode */
	zassert_equal(false, suit_execution_mode_booting(), "The device entered boot mode");
	/* ... and execution mode indicates update mode */
	zassert_equal(true, suit_execution_mode_updating(), "The device did not enter update mode");
	/* ... and the startup failure is correctly handled */
	check_startup_failure();
}

ZTEST(orchestrator_init_tests, test_empty_storage_with_fdfu_flag)
{
	/* GIVEN empty flash (suit storage is erased)... */
	setup_erased_flash();
	/* ... and update candidate flag is not set... */
	/* ... and foreground DFU flag is set */
	setup_fdfu_flag();

	/* WHEN orchestrator is initialized */
	int err = suit_orchestrator_init();

	/* THEN foreground DFU is triggered... */
	zassert_equal(EXECUTION_MODE_INVOKE_FOREGROUND_DFU, suit_execution_mode_get(),
		      "Foreground DFU mode not triggered");
	/* ... and orchestrator is initialized */
	zassert_equal(0, err, "Orchestrator not initialized");
	/* ... and execution mode does not indicate a failed state */
	zassert_equal(false, suit_execution_mode_failed(), "The device entered failed mode");
	/* ... and execution mode indicates boot mode */
	zassert_equal(true, suit_execution_mode_booting(), "The device did not enter boot mode");
	/* ... and execution mode does not indicate update mode */
	zassert_equal(false, suit_execution_mode_updating(), "The device entered update mode");
	/* ... and the startup failure is correctly handled */
	check_startup_failure();
}

ZTEST(orchestrator_init_tests, test_empty_storage_with_update_fdfu_flag)
{
	/* GIVEN empty flash (suit storage is erased)... */
	setup_erased_flash();
	/* ... and valid update candidate in suit storage... */
	setup_update_candidate(manifest_valid_buf, manifest_valid_len);
	/* ... and foreground DFU flag is set */
	setup_fdfu_flag();

	/* WHEN orchestrator is initialized */
	int err = suit_orchestrator_init();

	/* THEN foreground DFU is triggered... */
	zassert_equal(EXECUTION_MODE_INSTALL_FOREGROUND_DFU, suit_execution_mode_get(),
		      "Foreground DFU update not triggered");
	/* ... and orchestrator is initialized */
	zassert_equal(0, err, "Orchestrator not initialized");
	/* ... and execution mode does not indicate a failed state */
	zassert_equal(false, suit_execution_mode_failed(), "The device entered failed mode");
	/* ... and execution mode does not indicate boot mode */
	zassert_equal(false, suit_execution_mode_booting(), "The device entered boot mode");
	/* ... and execution mode indicates update mode */
	zassert_equal(true, suit_execution_mode_updating(), "The device did not enter update mode");
	/* ... and the startup failure is correctly handled */
	check_startup_failure();
}
```
